# N32G41x register map
Vendor: Nsingtech Ltd.; File version: 1.0
CPU: CM4 r0p1, little endian, no MPU, no FPU, 4 interrupt priority bits
Registers are 32-bit, read-write, reset 0x0 unless marked. A register's access mark holds for its fields unless they carry their own. Offsets are from the block's base; [hi:lo] are bit positions.

## I2C1 — Inter-Integrated Circuit
Base 0x40005400
Same registers: I2C2 0x40005800
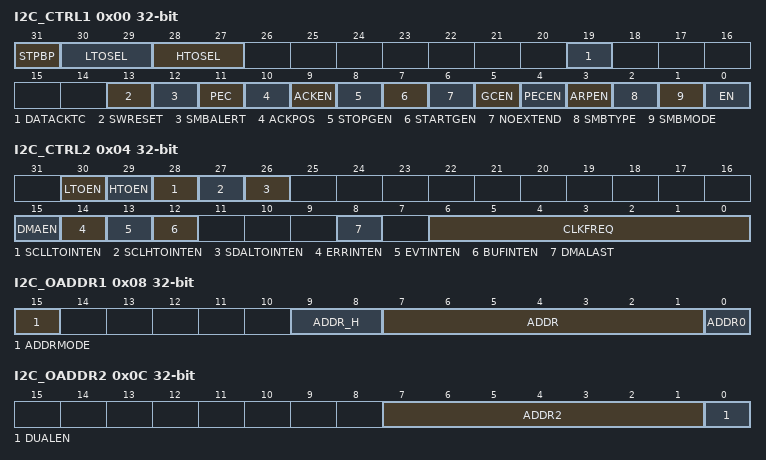
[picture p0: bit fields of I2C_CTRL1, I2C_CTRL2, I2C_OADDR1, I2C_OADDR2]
0x00 I2C_CTRL1 — I2C Control Register 1
  [31] STPBP — Stop bypass
  [30:29] LTOSEL — Low timeout threshold selection
  [28:27] HTOSEL — High timeout threshold selection
  [19] DATACKTC — Data ACK timing control
  [13] SWRESET — Software reset
  [12] SMBALERT — SMBus alert
  [11] PEC — Packet error checking
  [10] ACKPOS — Acknowledge/PEC position
  [9] ACKEN — Acknowledge enable
  [8] STOPGEN — Stop generation
  [7] STARTGEN — Start generation
  [6] NOEXTEND — Clock stretching disable
  [5] GCEN — General call enable
  [4] PECEN — PEC enable
  [3] ARPEN — ARP enable
  [2] SMBTYPE — SMBus type
  [1] SMBMODE — SMBus mode
  [0] EN — Peripheral enable
0x04 I2C_CTRL2 — I2C Control Register 2
  [30] LTOEN — SCL and SDA low timeout enable
  [29] HTOEN — High timeout enable
  [28] SCLLTOINTEN — SCL low timeout error interrupt enable
  [27] SCLHTOINTEN — SCL high timeout error interrupt enable
  [26] SDALTOINTEN — SDA low timeout error interrupt enable
  [15] DMAEN — DMA requests enable
  [14] ERRINTEN — Error interrupt enable
  [13] EVTINTEN — Event interrupt enable
  [12] BUFINTEN — Buffer interrupt enable
  [8] DMALAST — DMA last transfer
  [6:0] CLKFREQ — Peripheral clock frequency
0x08 I2C_OADDR1 — I2C Own Address Register 1
  [15] ADDRMODE — Addressing mode
  [9:8] ADDR_H — Interface address bits 9:8
  [7:1] ADDR — Interface address bits 7:1
  [0] ADDR0 — Interface address bit 0
0x0C I2C_OADDR2 — I2C Own Address Register 2
  [7:1] ADDR2 — Interface address bits 7:1
  [0] DUALEN — Dual addressing mode enable
0x10 I2C_DAT — I2C Data Register
  [7:0] DATA — 8-bit data register
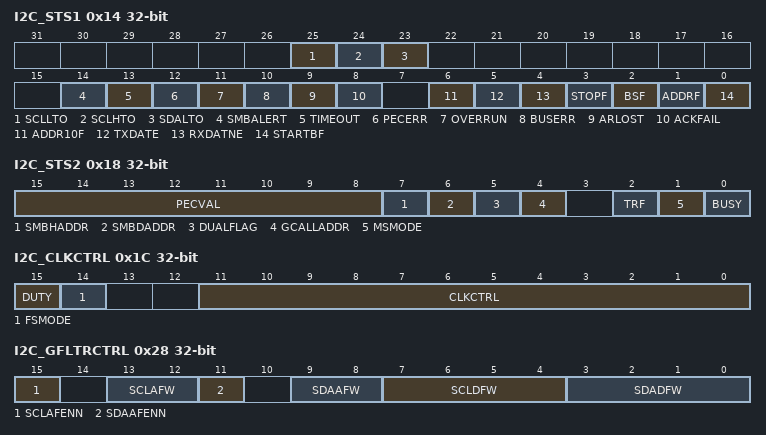
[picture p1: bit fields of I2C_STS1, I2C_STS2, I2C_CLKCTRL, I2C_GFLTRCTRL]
0x14 I2C_STS1 — I2C Status Register 1
  [25] SCLLTO — SCL low timeout error
  [24] SCLHTO — SCL high timeout error
  [23] SDALTO — SDA low timeout error
  [14] SMBALERT — SMBus alert
  [13] TIMEOUT — Timeout flag
  [12] PECERR — PEC error in reception
  [11] OVERRUN — Overrun/Underrun
  [10] BUSERR — Bus error
  [9] ARLOST — Arbitration lost
  [8] ACKFAIL — Acknowledge failure
  [6] ADDR10F ro — 10-bit header sent
  [5] TXDATE ro — Data register empty
  [4] RXDATNE ro — Data register not empty
  [3] STOPF ro — Stop condition detected
  [2] BSF ro — Byte transfer finished
  [1] ADDRF ro — Address sent/matched
  [0] STARTBF ro — Start bit
0x18 I2C_STS2 ro — I2C Status Register 2
  [15:8] PECVAL — Packet error checking register
  [7] SMBHADDR — SMBus host address
  [6] SMBDADDR — SMBus device default address
  [5] DUALFLAG
  [4] GCALLADDR — General call address
  [2] TRF — Transmitter/receiver
  [1] MSMODE — Master/slave mode
  [0] BUSY — Bus busy
0x1C I2C_CLKCTRL — I2C Clock Control Register
  [15] DUTY — Fast mode duty cycle
  [14] FSMODE — I2C fast mode selection
  [11:0] CLKCTRL — Clock control divider
0x20 I2C_TMRISE reset 0x2 — I2C Rise Time Register
  [5:0] TMRISE — Maximum rise time
0x28 I2C_GFLTRCTRL — I2C Filter Control Register
  [15] SCLAFENN — SCL analog filter enable
  [13:12] SCLAFW — SCL analog filter width
  [11] SDAAFENN — SDA analog filter enable
  [9:8] SDAAFW — SDA analog filter width
  [7:4] SCLDFW — SCL digital filter width
  [3:0] SDADFW — SDA digital filter width

## BTIM1 — Basic Timer 1
Base 0x40001000
Same registers: BTIM2 0x40001400
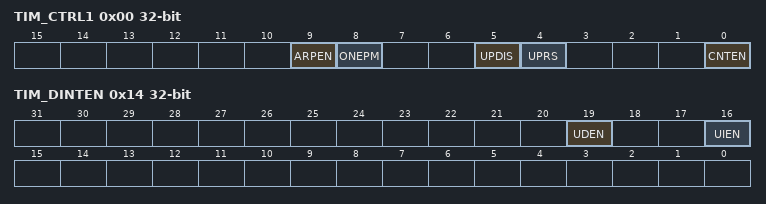
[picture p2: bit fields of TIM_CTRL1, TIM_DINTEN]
0x00 TIM_CTRL1 — TIM Control Register 1
  [9] ARPEN — Auto-reload preload enable
  [8] ONEPM — One pulse mode
  [5] UPDIS — Update disable
  [4] UPRS — Update request source
  [0] CNTEN — Counter enable
0x04 TIM_CTRL2 — TIM Control Register 2
  [15:12] MMSEL — Master mode selection
0x08 TIM_STS — TIM Status Register
  [16] UDITF — Update interrupt flag
0x0C TIM_EVTGEN wo — TIM Event Generation Register
  [8] UDGN — Update generation
0x14 TIM_DINTEN — TIM DMA/Interrupt Enable Register
  [19] UDEN — Update DMA request enable
  [16] UIEN — Update interrupt enable
0x40 TIM_PSC — TIM Prescaler Register
  [15:0] PSC — Prescaler value
0x44 TIM_AR reset 0xFFFF — TIM Auto-Reload Register
  [15:0] AR — Auto-reload value
0x48 TIM_CNT — TIM Counter Register
  [15:0] CNT — Counter value
